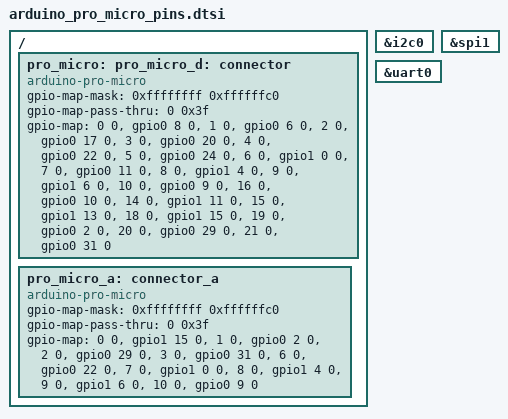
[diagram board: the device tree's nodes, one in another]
/*
 * Copyright (c) 2020 Pete Johanson
 *
 * SPDX-License-Identifier: MIT
 */

/ {
	pro_micro: connector {
		compatible = "arduino-pro-micro";
		#gpio-cells = <2>;
		gpio-map-mask = <0xffffffff 0xffffffc0>;
		gpio-map-pass-thru = <0 0x3f>;
		gpio-map
			= <0 0 &gpio0 8 0>
			, <1 0 &gpio0 6 0>
			, <2 0 &gpio0 17 0>
			, <3 0 &gpio0 20 0>
			, <4 0 &gpio0 22 0>
			, <5 0 &gpio0 24 0>
			, <6 0 &gpio1 0 0>
			, <7 0 &gpio0 11 0>
			, <8 0 &gpio1 4 0>
			, <9 0 &gpio1 6 0>
			, <10 0 &gpio0 9 0>
			, <16 0 &gpio0 10 0>
			, <14 0 &gpio1 11 0>
			, <15 0 &gpio1 13 0>
			, <18 0 &gpio1 15 0>
			, <19 0 &gpio0 2 0>
			, <20 0 &gpio0 29 0>
			, <21 0 &gpio0 31 0>
			;
	};

	pro_micro_a: connector_a {
		compatible = "arduino-pro-micro";
		#gpio-cells = <2>;
		gpio-map-mask = <0xffffffff 0xffffffc0>;
		gpio-map-pass-thru = <0 0x3f>;
		gpio-map
			= <0 0 &gpio1 15 0>
			, <1 0 &gpio0 2 0>
			, <2 0 &gpio0 29 0>
			, <3 0 &gpio0 31 0>
			, <6 0 &gpio0 22 0>
			, <7 0 &gpio1 0 0>
			, <8 0 &gpio1 4 0>
			, <9 0 &gpio1 6 0>
			, <10 0 &gpio0 9 0>
			;
	};
};

pro_micro_d: &pro_micro {};
pro_micro_i2c: &i2c0 {};
pro_micro_spi: &spi1 {};
pro_micro_serial: &uart0 {};
